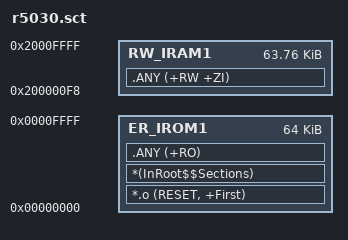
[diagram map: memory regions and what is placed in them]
/*
 * MPS2 CMSIS Library
 *
 * Copyright (c) 2006-2017 ARM Limited. All rights reserved.
 *
 * SPDX-License-Identifier: Apache-2.0
 *
 * Licensed under the Apache License, Version 2.0 (the License); you may
 * not use this file except in compliance with the License.
 * You may obtain a copy of the License at
 *
 * http://www.apache.org/licenses/LICENSE-2.0
 *
 * Unless required by applicable law or agreed to in writing, software
 * distributed under the License is distributed on an AS IS BASIS, WITHOUT
 * WARRANTIES OR CONDITIONS OF ANY KIND, either express or implied.
 * See the License for the specific language governing permissions and
 * limitations under the License.
 *
 *************************************************************
 *** Scatter-Loading Description File                      ***
 *************************************************************
 */

; R5030_APPS_PROC: 64 KB FLASH (0x10000) + 64 KB SRAM (0x10000)
LR_IROM1 0x00000000 0x10000  {    ; load region size_region
  ER_IROM1 0x00000000 0x00010000  {  ; load address = execution address
   *.o (RESET, +First)
   *(InRoot$$Sections)
   .ANY (+RO)
  }

  ; Total: 62 vectors = 248 bytes (0xF8) to be reserved in RAM
  RW_IRAM1 (0x20000000+0xF8) (0x10000-0xF8)  {  ; RW data
   .ANY (+RW +ZI)
  }
}

